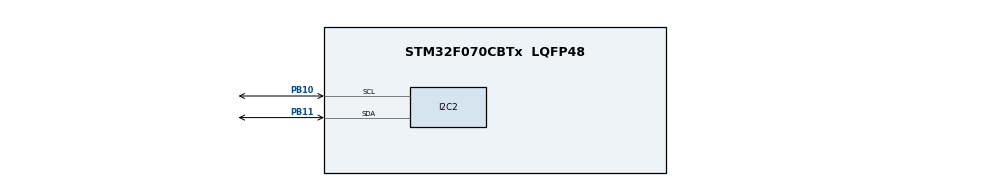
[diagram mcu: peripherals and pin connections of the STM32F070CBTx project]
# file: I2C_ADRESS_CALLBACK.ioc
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I2C2.NoStretchMode=I2C_NOSTRETCH_ENABLE
I2C2.OwnAddress=0x50
Mcu.Family=STM32F0
Mcu.Name=STM32F070CBTx
Mcu.Package=LQFP48
NVIC.I2C2_IRQn=true\:0\:0\:false\:false\:true\:true\:true\:true
PA13.Mode=Serial_Wire
PA13.Signal=SYS_SWDIO
PA14.Mode=Serial_Wire
PA14.Signal=SYS_SWCLK
PB10.Mode=I2C
PB10.Signal=I2C2_SCL
PB11.Mode=I2C
PB11.Signal=I2C2_SDA
PF0-OSC_IN.Mode=HSE-External-Oscillator
PF0-OSC_IN.Signal=RCC_OSC_IN
PF1-OSC_OUT.Mode=HSE-External-Oscillator
PF1-OSC_OUT.Signal=RCC_OSC_OUT
ProjectManager.HeapSize=0x200
ProjectManager.StackSize=0x400
ProjectManager.TargetToolchain=STM32CubeIDE
board=custom

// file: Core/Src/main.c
/* USER CODE BEGIN Header */
/**
  ******************************************************************************
  * @file           : main.c
  * @brief          : Main program body
  ******************************************************************************
  * @attention
  *
  * Copyright (c) 2023 STMicroelectronics.
  * All rights reserved.
  *
  * This software is licensed under terms that can be found in the LICENSE file
  * in the root directory of this software component.
  * If no LICENSE file comes with this software, it is provided AS-IS.
  *
  ******************************************************************************
  */
/* USER CODE END Header */
#include "main.h"

I2C_HandleTypeDef hi2c2;

void SystemClock_Config(void);
static void MX_GPIO_Init(void);
static void MX_I2C2_Init(void);

uint8_t atest_edid[129] = {
	0x00,0xff,0xff,0xff,0xff,0xff,0xff,0x00,0x1e,0x6d,0x33,0x5b,0xfa,0xf0,0x04,0x00,0x07,0x1d,0x01,0x03,0x10,0x30,0x1b,0x78,0xea,0x31,0x35,0xa5,0x55,0x4e,0xa1,0x26,0x0c,0x50,0x54,0xa5,0x4b,0x00,0x01,0x01,0x81,0x80,0x95,0x00,0xb3,0x00,0x01,0x01,0x01,0x01,0x81,0xc0,0x01,0x01,0x02,0x3a,0x80,0x18,0x71,0x38,0x2d,0x40,0x58,0x2c,0x45,0x00,0xe0,0x0e,0x11,0x00,0x00,0x1e,0x00,0x00,0x00,0xfd,0x00,0x28,0x4b,0x1e,0x55,0x12,0x00,0x0a,0x20,0x20,0x20,0x20,0x20,0x20,0x00,0x00,0x00,0xfc,0x00,0x4d,0x45,0x47,0x52,0x45,0x20,0x53,0x43,0x52,0x45,0x45,0x4e,0x0a,0x00,0x00,0x00,0xff,0x00,0x39,0x30,0x37,0x4e,0x54,0x59,0x54,0x39,0x48,0x38,0x33,0x34,0x0a,0x00,0xb1,0x00
}; //DEL2011_A37291D73923

uint8_t atest_edid_sub[128] = {
	0x00,0xff,0xff,0xff,0xff,0xff,0xff,0x00,0x1e,0x6d,0x33,0x5b,0xfa,0xf0,0x04,0x00,0x07,0x1d,0x01,0x03,0x10,0x30,0x1b,0x78,0xea,0x31,0x35,0xa5,0x55,0x4e,0xa1,0x26,0x0c,0x50,0x54,0xa5,0x4b,0x00,0x01,0x01,0x81,0x80,0x95,0x00,0xb3,0x00,0x01,0x01,0x01,0x01,0x81,0xc0,0x01,0x01,0x02,0x3a,0x80,0x18,0x71,0x38,0x2d,0x40,0x58,0x2c,0x45,0x00,0xe0,0x0e,0x11,0x00,0x00,0x1e,0x00,0x00,0x00,0xfd,0x00,0x28,0x4b,0x1e,0x55,0x12,0x00,0x0a,0x20,0x20,0x20,0x20,0x20,0x20,0x00,0x00,0x00,0xfc,0x00,0x4d,0x45,0x47,0x52,0x45,0x20,0x53,0x43,0x52,0x45,0x45,0x4e,0x0a,0x00,0x00,0x00,0xff,0x00,0x39,0x30,0x37,0x4e,0x54,0x59,0x54,0x39,0x48,0x38,0x33,0x34,0x0a,0x00,0xb1
}; //DEL2011_A37291D73923
uint8_t wtf[256];
uint8_t buffer_tx[8]={69,69,69,69,69,69,69,69};
uint8_t buffer_rx[8]={0x08,69,0xff,69,0xff,69,0xff,69};
uint8_t *pointer_pro;

int counter=0;
int last_time_send_edid=0;
static uint8_t i=128;
int counter2=0;
int main(void)
{

  /* MCU Configuration--------------------------------------------------------*/

  /* Reset of all peripherals, Initializes the Flash interface and the Systick. */
  HAL_Init();

  /* Configure the system clock */
  SystemClock_Config();

  /* Initialize all configured peripherals */
  MX_GPIO_Init();
  MX_I2C2_Init();
  /* USER CODE BEGIN 2 */
  HAL_I2C_DeInit(&hi2c2);
  HAL_I2C_Init(&hi2c2);
  HAL_Delay(200);
  if(HAL_I2C_EnableListen_IT(&hi2c2)!=HAL_OK)
	  Error_Handler();
  /* USER CODE END 2 */

  /* Infinite loop */
  while (1)
  {

  }
}
void HAL_I2C_SlaveRxCpltCallback(I2C_HandleTypeDef *hi2c)
{

	HAL_I2C_Slave_Transmit_DMA(hi2c, atest_edid_sub + buffer_rx[0], 128);
//	HAL_I2C_EnableListen_IT(hi2c);
}
void HAL_I2C_SlaveTxCpltCallback(I2C_HandleTypeDef *hi2c)
{
	HAL_I2C_EnableListen_IT(hi2c);

}

HAL_StatusTypeDef HAL_I2C_EnableListen_IT2(I2C_HandleTypeDef *hi2c);
void HAL_I2C_AddrCallback(I2C_HandleTypeDef *hi2c, uint8_t TransferDirection, uint16_t AddrMatchCode)
{
//	HAL_I2C_EnableListen_IT(hi2c);
	counter++;
	if(TransferDirection==I2C_DIRECTION_TRANSMIT)
		HAL_I2C_Slave_Seq_Receive_IT(hi2c, buffer_rx, 1, I2C_FIRST_AND_LAST_FRAME);
	else if(TransferDirection==I2C_DIRECTION_RECEIVE)
	{
		//do nothing...

	}
//	HAL_I2C_EnableListen_IT2(hi2c);
}

void SystemClock_Config(void)
{
  RCC_OscInitTypeDef RCC_OscInitStruct = {0};
  RCC_ClkInitTypeDef RCC_ClkInitStruct = {0};

  /** Initializes the RCC Oscillators according to the specified parameters
  * in the RCC_OscInitTypeDef structure.
  */
  RCC_OscInitStruct.OscillatorType = RCC_OSCILLATORTYPE_HSI;
  RCC_OscInitStruct.HSIState = RCC_HSI_ON;
  RCC_OscInitStruct.HSICalibrationValue = RCC_HSICALIBRATION_DEFAULT;
  RCC_OscInitStruct.PLL.PLLState = RCC_PLL_NONE;
  if (HAL_RCC_OscConfig(&RCC_OscInitStruct) != HAL_OK)
  {
    Error_Handler();
  }

  /** Initializes the CPU, AHB and APB buses clocks
  */
  RCC_ClkInitStruct.ClockType = RCC_CLOCKTYPE_HCLK|RCC_CLOCKTYPE_SYSCLK
                              |RCC_CLOCKTYPE_PCLK1;
  RCC_ClkInitStruct.SYSCLKSource = RCC_SYSCLKSOURCE_HSI;
  RCC_ClkInitStruct.AHBCLKDivider = RCC_SYSCLK_DIV1;
  RCC_ClkInitStruct.APB1CLKDivider = RCC_HCLK_DIV1;

  if (HAL_RCC_ClockConfig(&RCC_ClkInitStruct, FLASH_LATENCY_0) != HAL_OK)
  {
    Error_Handler();
  }
}

static void MX_I2C2_Init(void)
{

  hi2c2.Instance = I2C2;
  hi2c2.Init.Timing = 0x2000090E;
  hi2c2.Init.OwnAddress1 = 160;
  hi2c2.Init.AddressingMode = I2C_ADDRESSINGMODE_7BIT;
  hi2c2.Init.DualAddressMode = I2C_DUALADDRESS_DISABLE;
  hi2c2.Init.OwnAddress2 = 0;
  hi2c2.Init.OwnAddress2Masks = I2C_OA2_NOMASK;
  hi2c2.Init.GeneralCallMode = I2C_GENERALCALL_DISABLE;
  hi2c2.Init.NoStretchMode = I2C_NOSTRETCH_ENABLE;
  if (HAL_I2C_Init(&hi2c2) != HAL_OK)
  {
    Error_Handler();
  }

  /** Configure Analogue filter
  */
  if (HAL_I2CEx_ConfigAnalogFilter(&hi2c2, I2C_ANALOGFILTER_ENABLE) != HAL_OK)
  {
    Error_Handler();
  }

  /** Configure Digital filter
  */
  if (HAL_I2CEx_ConfigDigitalFilter(&hi2c2, 0) != HAL_OK)
  {
    Error_Handler();
  }

}

static void MX_GPIO_Init(void)
{

  /* GPIO Ports Clock Enable */
  __HAL_RCC_GPIOF_CLK_ENABLE();
  __HAL_RCC_GPIOB_CLK_ENABLE();
  __HAL_RCC_GPIOA_CLK_ENABLE();

}

void Error_Handler(void)
{
  __disable_irq();
  while (1)
  {
  }
}
